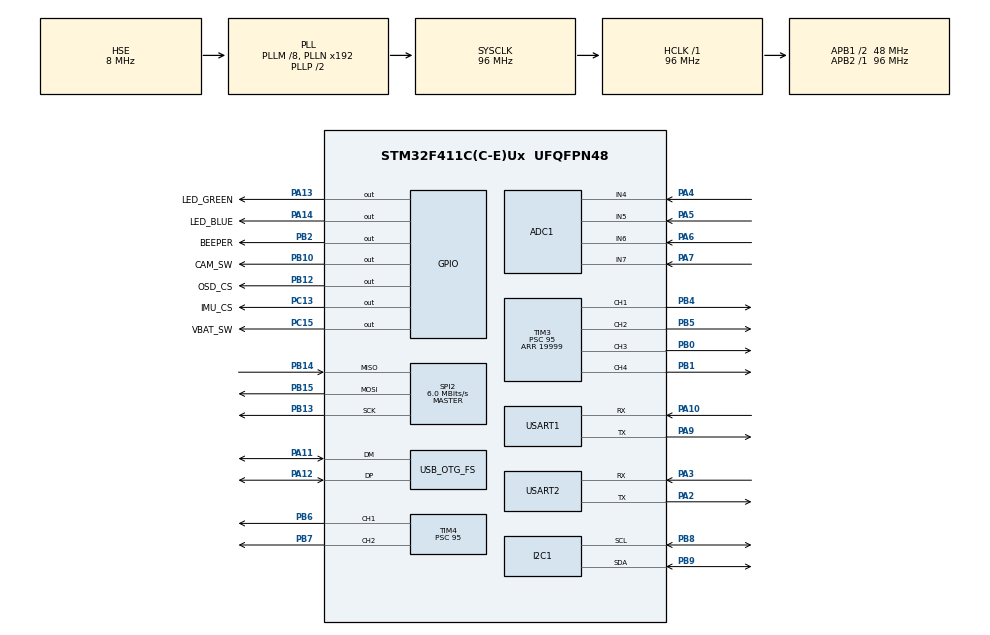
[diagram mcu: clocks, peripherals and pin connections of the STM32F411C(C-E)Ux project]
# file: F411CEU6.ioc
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ADC1.Channel-0\#ChannelRegularConversion=ADC_CHANNEL_4
ADC1.Channel-1\#ChannelRegularConversion=ADC_CHANNEL_5
ADC1.Channel-2\#ChannelRegularConversion=ADC_CHANNEL_6
ADC1.Channel-3\#ChannelRegularConversion=ADC_CHANNEL_7
ADC1.ContinuousConvMode=ENABLE
ADC1.DMAContinuousRequests=ENABLE
ADC1.DiscontinuousConvMode=DISABLE
ADC1.NbrOfConversion=4
ADC1.NbrOfConversionFlag=1
ADC1.Rank-0\#ChannelRegularConversion=1
ADC1.Rank-1\#ChannelRegularConversion=2
ADC1.Rank-2\#ChannelRegularConversion=3
ADC1.Rank-3\#ChannelRegularConversion=4
ADC1.SamplingTime-0\#ChannelRegularConversion=ADC_SAMPLETIME_480CYCLES
ADC1.SamplingTime-1\#ChannelRegularConversion=ADC_SAMPLETIME_480CYCLES
ADC1.SamplingTime-2\#ChannelRegularConversion=ADC_SAMPLETIME_480CYCLES
ADC1.SamplingTime-3\#ChannelRegularConversion=ADC_SAMPLETIME_480CYCLES
ADC1.ScanConvMode=ENABLE
ADC1.master=1
Dma.ADC1.0.Direction=DMA_PERIPH_TO_MEMORY
Dma.ADC1.0.FIFOMode=DMA_FIFOMODE_DISABLE
Dma.ADC1.0.Instance=DMA2_Stream0
Dma.ADC1.0.MemDataAlignment=DMA_MDATAALIGN_HALFWORD
Dma.ADC1.0.MemInc=DMA_MINC_ENABLE
Dma.ADC1.0.Mode=DMA_CIRCULAR
Dma.ADC1.0.PeriphDataAlignment=DMA_PDATAALIGN_HALFWORD
Dma.ADC1.0.PeriphInc=DMA_PINC_DISABLE
Dma.ADC1.0.Priority=DMA_PRIORITY_LOW
Dma.Request0=ADC1
I2C1.I2C_Mode=I2C_Fast
Mcu.Family=STM32F4
Mcu.Name=STM32F411C(C-E)Ux
Mcu.Package=UFQFPN48
NVIC.DMA2_Stream0_IRQn=true\:0\:0\:false\:false\:true\:false\:true\:true
NVIC.OTG_FS_IRQn=true\:0\:0\:false\:false\:true\:false\:true\:true
NVIC.PriorityGroup=NVIC_PRIORITYGROUP_4
PA10.Mode=Asynchronous
PA10.Signal=USART1_RX
PA11.Mode=Device_Only
PA11.Signal=USB_OTG_FS_DM
PA12.Mode=Device_Only
PA12.Signal=USB_OTG_FS_DP
PA13.GPIO_Label=LED_GREEN
PA13.Signal=GPIO_Output
PA14.GPIO_Label=LED_BLUE
PA14.Signal=GPIO_Output
PA2.Mode=Asynchronous
PA2.Signal=USART2_TX
PA3.Mode=Asynchronous
PA3.Signal=USART2_RX
PA4.Signal=ADCx_IN4
PA5.Signal=ADCx_IN5
PA6.Signal=ADCx_IN6
PA7.Signal=ADCx_IN7
PA9.Mode=Asynchronous
PA9.Signal=USART1_TX
PB0.Signal=S_TIM3_CH3
PB1.Signal=S_TIM3_CH4
PB10.GPIO_Label=CAM_SW
PB10.Signal=GPIO_Output
PB12.GPIO_Label=OSD_CS
PB12.PinState=GPIO_PIN_SET
PB12.Signal=GPIO_Output
PB13.Mode=Full_Duplex_Master
PB13.Signal=SPI2_SCK
PB14.Mode=Full_Duplex_Master
PB14.Signal=SPI2_MISO
PB15.Mode=Full_Duplex_Master
PB15.Signal=SPI2_MOSI
PB2.GPIO_Label=BEEPER
PB2.Signal=GPIO_Output
PB4.Signal=S_TIM3_CH1
PB5.Signal=S_TIM3_CH2
PB6.Signal=S_TIM4_CH1
PB7.Signal=S_TIM4_CH2
PB8.Mode=I2C
PB8.Signal=I2C1_SCL
PB9.Mode=I2C
PB9.Signal=I2C1_SDA
PC13-ANTI_TAMP.GPIO_Label=IMU_CS
PC13-ANTI_TAMP.PinState=GPIO_PIN_SET
PC13-ANTI_TAMP.Signal=GPIO_Output
PC15-OSC32_OUT.GPIO_Label=VBAT_SW
PC15-OSC32_OUT.Signal=GPIO_Output
PH0\ -\ OSC_IN.Mode=HSE-External-Oscillator
PH0\ -\ OSC_IN.Signal=RCC_OSC_IN
PH1\ -\ OSC_OUT.Mode=HSE-External-Oscillator
PH1\ -\ OSC_OUT.Signal=RCC_OSC_OUT
ProjectManager.HeapSize=0x200
ProjectManager.StackSize=0x800
ProjectManager.TargetToolchain=STM32CubeIDE
RCC.48MHZClocksFreq_Value=48000000
RCC.AHBFreq_Value=96000000
RCC.APB1CLKDivider=RCC_HCLK_DIV2
RCC.APB1Freq_Value=48000000
RCC.APB1TimFreq_Value=96000000
RCC.APB2Freq_Value=96000000
RCC.APB2TimFreq_Value=96000000
RCC.CortexFreq_Value=96000000
RCC.HCLKFreq_Value=96000000
RCC.HSE_VALUE=8000000
RCC.HSI_VALUE=16000000
RCC.LSE_VALUE=32768
RCC.PLLM=8
RCC.SYSCLKFreq_VALUE=96000000
RCC.SYSCLKSource=RCC_SYSCLKSOURCE_PLLCLK
RCC.VCOOutputFreq_Value=192000000
SH.ADCx_IN4.0=ADC1_IN4,IN4
SH.ADCx_IN5.0=ADC1_IN5,IN5
SH.ADCx_IN6.0=ADC1_IN6,IN6
SH.ADCx_IN7.0=ADC1_IN7,IN7
SH.S_TIM3_CH1.0=TIM3_CH1,PWM Generation1 CH1
SH.S_TIM3_CH2.0=TIM3_CH2,PWM Generation2 CH2
SH.S_TIM3_CH3.0=TIM3_CH3,PWM Generation3 CH3
SH.S_TIM3_CH4.0=TIM3_CH4,PWM Generation4 CH4
SH.S_TIM4_CH1.0=TIM4_CH1,PWM Generation1 CH1
SH.S_TIM4_CH2.0=TIM4_CH2,PWM Generation2 CH2
SPI2.BaudRatePrescaler=SPI_BAUDRATEPRESCALER_8
SPI2.CalculateBaudRate=6.0 MBits/s
SPI2.Direction=SPI_DIRECTION_2LINES
SPI2.Mode=SPI_MODE_MASTER
SPI2.VirtualType=VM_MASTER
TIM3.Channel-PWM\ Generation1\ CH1=TIM_CHANNEL_1
TIM3.Channel-PWM\ Generation2\ CH2=TIM_CHANNEL_2
TIM3.Channel-PWM\ Generation3\ CH3=TIM_CHANNEL_3
TIM3.Channel-PWM\ Generation4\ CH4=TIM_CHANNEL_4
TIM3.Period=19999
TIM3.Prescaler=95
TIM4.Channel-PWM\ Generation1\ CH1=TIM_CHANNEL_1
TIM4.Channel-PWM\ Generation2\ CH2=TIM_CHANNEL_2
TIM4.Period=19999
TIM4.Prescaler=95
USART1.VirtualMode=VM_ASYNC
USART2.VirtualMode=VM_ASYNC
USB_DEVICE.CLASS_NAME_FS=CDC
USB_DEVICE.VirtualMode=Cdc
USB_DEVICE.VirtualModeFS=Cdc_FS
USB_OTG_FS.VirtualMode=Device_Only
VP_USB_DEVICE_VS_USB_DEVICE_CDC_FS.Mode=CDC_FS
board=custom

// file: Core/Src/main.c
/* USER CODE BEGIN Header */
/**
  ******************************************************************************
  * @file           : main.c
  * @brief          : Main program body
  ******************************************************************************
  * @attention
  *
  * Copyright (c) 2026 STMicroelectronics.
  * All rights reserved.
  *
  * This software is licensed under terms that can be found in the LICENSE file
  * in the root directory of this software component.
  * If no LICENSE file comes with this software, it is provided AS-IS.
  *
  ******************************************************************************
  */
/* USER CODE END Header */
#include "main.h"
#include "adc.h"
#include "dma.h"
#include "i2c.h"
#include "spi.h"
#include "tim.h"
#include "usart.h"
#include "usb_device.h"
#include "gpio.h"

/* USER CODE BEGIN Includes */
#include "bootloader.h"
#include "bench_commands.h"
/* USER CODE END Includes */

void SystemClock_Config(void);

int main(void)
{
  /* USER CODE BEGIN 1 */
  /* Если перед сбросом попросили DFU - уходим в ROM-загрузчик */
  Bootloader_CheckAndJump();
  /* USER CODE END 1 */

  /* MCU Configuration--------------------------------------------------------*/

  /* Reset of all peripherals, Initializes the Flash interface and the Systick. */
  HAL_Init();

  /* Configure the system clock */
  SystemClock_Config();

  /* Initialize all configured peripherals */
  MX_GPIO_Init();
  MX_DMA_Init();
  MX_USB_DEVICE_Init();
  MX_ADC1_Init();
  MX_I2C1_Init();
  MX_SPI2_Init();
  MX_TIM3_Init();
  MX_TIM4_Init();
  MX_USART1_UART_Init();
  MX_USART2_UART_Init();
  /* USER CODE BEGIN 2 */
  /* Светодиоды на SWD-пинах (PA13/PA14), поэтому SWD нет - только DFU */
  bench_init();
  /* USER CODE END 2 */

  /* Infinite loop */
  while (1)
  {

    /* USER CODE BEGIN 3 */
    bench_poll();
    Bootloader_Poll();
  }
  /* USER CODE END 3 */
}

void SystemClock_Config(void)
{
  RCC_OscInitTypeDef RCC_OscInitStruct = {0};
  RCC_ClkInitTypeDef RCC_ClkInitStruct = {0};

  /** Configure the main internal regulator output voltage
  */
  __HAL_RCC_PWR_CLK_ENABLE();
  __HAL_PWR_VOLTAGESCALING_CONFIG(PWR_REGULATOR_VOLTAGE_SCALE1);

  /** Initializes the RCC Oscillators according to the specified parameters
  * in the RCC_OscInitTypeDef structure.
  */
  RCC_OscInitStruct.OscillatorType = RCC_OSCILLATORTYPE_HSE;
  RCC_OscInitStruct.HSEState = RCC_HSE_ON;
  RCC_OscInitStruct.PLL.PLLState = RCC_PLL_ON;
  RCC_OscInitStruct.PLL.PLLSource = RCC_PLLSOURCE_HSE;
  RCC_OscInitStruct.PLL.PLLM = 8;
  RCC_OscInitStruct.PLL.PLLN = 192;
  RCC_OscInitStruct.PLL.PLLP = RCC_PLLP_DIV2;
  RCC_OscInitStruct.PLL.PLLQ = 4;
  if (HAL_RCC_OscConfig(&RCC_OscInitStruct) != HAL_OK)
  {
    Error_Handler();
  }

  /** Initializes the CPU, AHB and APB buses clocks
  */
  RCC_ClkInitStruct.ClockType = RCC_CLOCKTYPE_HCLK|RCC_CLOCKTYPE_SYSCLK
                              |RCC_CLOCKTYPE_PCLK1|RCC_CLOCKTYPE_PCLK2;
  RCC_ClkInitStruct.SYSCLKSource = RCC_SYSCLKSOURCE_PLLCLK;
  RCC_ClkInitStruct.AHBCLKDivider = RCC_SYSCLK_DIV1;
  RCC_ClkInitStruct.APB1CLKDivider = RCC_HCLK_DIV2;
  RCC_ClkInitStruct.APB2CLKDivider = RCC_HCLK_DIV1;

  if (HAL_RCC_ClockConfig(&RCC_ClkInitStruct, FLASH_LATENCY_3) != HAL_OK)
  {
    Error_Handler();
  }
}

void Error_Handler(void)
{
  __disable_irq();
  while (1)
  {
  }
}
